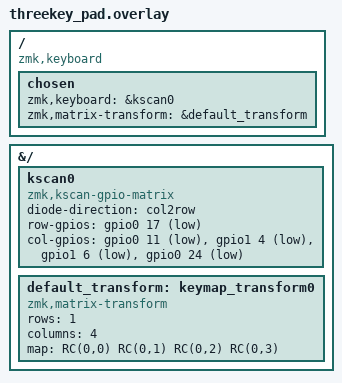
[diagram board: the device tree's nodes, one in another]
#include <dt-bindings/zmk/matrix_transform.h>

/ {
    compatible = "zmk,keyboard";

    chosen {
        zmk,keyboard = &kscan0;
        zmk,matrix-transform = &default_transform;
    };
};

&{/} {
    kscan0: kscan0 {
        compatible = "zmk,kscan-gpio-matrix";
        diode-direction = "col2row";

        row-gpios = <&gpio0 17 (GPIO_PULL_UP | GPIO_ACTIVE_LOW)>;
        col-gpios = <&gpio0 11 GPIO_ACTIVE_LOW>,
                    <&gpio1 4  GPIO_ACTIVE_LOW>,
                    <&gpio1 6  GPIO_ACTIVE_LOW>,
                    <&gpio0 24 GPIO_ACTIVE_LOW>;
    };

    default_transform: keymap_transform0 {
        compatible = "zmk,matrix-transform";

        rows = <1>;
        columns = <4>;

        map = <RC(0,0) RC(0,1) RC(0,2) RC(0,3)>;
    };
};
